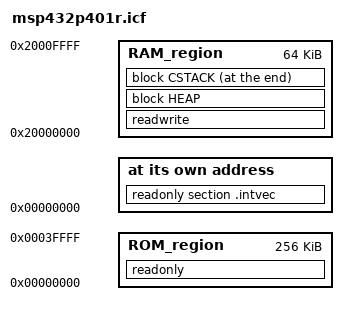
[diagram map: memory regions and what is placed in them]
/******************************************************
 * IAR linker script for Texas Instruments MSP432P401R
 ******************************************************/

/* Device specific values */

define symbol ROM_START   = 0x00000000;
define symbol ROM_SIZE    = 0x00040000;
define symbol RAM_START   = 0x20000000;
define symbol RAM_SIZE    = 0x00010000;

define symbol HEAP_SIZE      = 0x8000;
define symbol ISR_STACK_SIZE = 0x400;

/* Common - Do not change */

if (!isdefinedsymbol(MBED_APP_START)) {
    define symbol MBED_APP_START = ROM_START;
}

if (!isdefinedsymbol(MBED_APP_SIZE)) {
    define symbol MBED_APP_SIZE = ROM_SIZE;
}

define symbol RAM_REGION_START = RAM_START;
define symbol RAM_REGION_SIZE  = RAM_SIZE;

define memory mem with size = 4G;
define region ROM_region = mem:[from MBED_APP_START   size MBED_APP_SIZE];
define region RAM_region = mem:[from RAM_REGION_START size RAM_REGION_SIZE];

define block CSTACK    with alignment = 8, size = ISR_STACK_SIZE { };
define block HEAP      with alignment = 8, size = HEAP_SIZE      { };

initialize by copy { readwrite };
do not initialize  { section .noinit };

place at address mem: MBED_APP_START { readonly section .intvec };

place in ROM_region        { readonly };
place in RAM_region        { readwrite, block HEAP };
place at end of RAM_region { block CSTACK };
